# nrf7120E_enga_application register map
Vendor: Nordic Semiconductor; Series: nrf71; File version: 1
CPU: CM33 r0p4, little endian, MPU, FPU, 3 interrupt priority bits, 270 interrupts, 4 SAU regions
Registers are 32-bit, read-write, reset 0x0 unless marked. A register's access mark holds for its fields unless they carry their own. Offsets are from the block's base; [hi:lo] are bit positions; {n}, {i} and the like mark numbered series; 'fields as' and 'values as' point back to an identical list.

## GLOBAL_TAD_NS — Trace and debug control 0
Base 0x40053000
Same registers: GLOBAL_TAD_S 0x50053000
0x400 SYSPWRUPREQ — System power-up request
  [0] ACTIVE — Activate power-up request
    0=NotActive (Power-up request not active); 1=Active (Power-up request active)
0x404 DBGPWRUPREQ — Debug power-up request
  fields as SYSPWRUPREQ
0x500 ENABLE — Enable debug domain and acquire selected GPIOs
  [0] ENABLE
    0=DISABLED (Disable debug domain and release selected GPIOs); 1=ENABLED (Enable debug domain and acquire selected GPIOs)
0x518 TRACEPORTSPEED
  [1:0] TRACEPORTSPEED — Trace port speed is divided from CPU clock. The TRACECLK pin output will be divided again by two from the trace port clock.
    0=DIV1 (Trace port speed equals CPU clock); 1=DIV2 (Trace port speed equals CPU clock divided by 2); 2=DIV4 (Trace port speed equals CPU clock divided by 4); 3=DIV32 (Trace port speed equals CPU clock divided by 32)
0x520 TINSTANCE — SW-DP Target instance
  [3:0] TINSTANCE — TINSTANCE bits are used in the SW-DP DLPIDR.TINSTANCE field.

## GLOBAL_AXONS_NS — Neural processing unit (NPU) 0
Base 0x40056000
Same registers: GLOBAL_AXONS_S 0x50056000
0x400 ENABLE — Enable AXONS.
  [0] EN — Enable
    0=Disabled (AXONS disabled (powered off).); 1=Enabled (AXONS enabled.)
0x404 STATUS ro
  [0] READY — AXONS ready
    0=NotReady (AXONS is not yet accessible); 1=Ready (AXONS is accessible)

## GLOBAL_EGU00_NS — Event generator unit 0
Base 0x40058000
Same registers: GLOBAL_EGU10_NS 0x40087000, GLOBAL_EGU20_NS 0x400C9000, GLOBAL_EGU00_S 0x50058000, GLOBAL_EGU10_S 0x50087000, GLOBAL_EGU20_S 0x500C9000
{0x0+4i} TASKS_TRIGGER[{i}] (i=0..15) wo — Description collection: Trigger n for triggering the corresponding TRIGGERED[n] event
  [0] TASKS_TRIGGER — Trigger n for triggering the corresponding TRIGGERED[n] event
    1=Trigger task
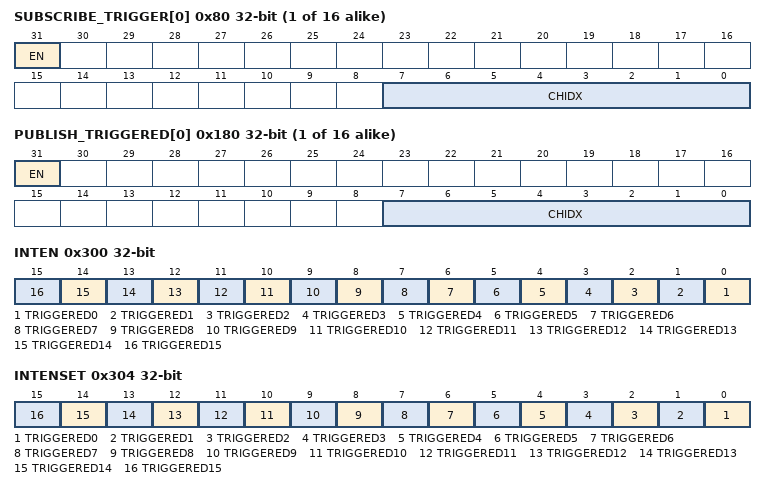
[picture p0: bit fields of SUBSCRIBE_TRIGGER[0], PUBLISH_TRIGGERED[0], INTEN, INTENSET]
{0x80+4i} SUBSCRIBE_TRIGGER[{i}] (i=0..15) — Description collection: Subscribe configuration for task TRIGGER[n]
  [31] EN
    0=Disabled (Disable subscription); 1=Enabled (Enable subscription)
  [7:0] CHIDX — DPPI channel that task TRIGGER[n] will subscribe to
{0x100+4i} EVENTS_TRIGGERED[{i}] (i=0..15) — Description collection: Event number n generated by triggering the corresponding TRIGGER[n] task
  [0] EVENTS_TRIGGERED — Event number n generated by triggering the corresponding TRIGGER[n] task
    0=NotGenerated (Event not generated); 1=Generated (Event generated)
{0x180+4i} PUBLISH_TRIGGERED[{i}] (i=0..15) — Description collection: Publish configuration for event TRIGGERED[n]
  [31] EN
    0=Disabled (Disable publishing); 1=Enabled (Enable publishing)
  [7:0] CHIDX — DPPI channel that event TRIGGERED[n] will publish to
0x300 INTEN — Enable or disable interrupt
  [all] fields
    0=Disabled; 1=Enabled
  [n] TRIGGERED{n} (n=0..15) — Enable or disable interrupt for event TRIGGERED[{n}]
0x304 INTENSET — Enable interrupt
  [all] fields
    on read: 0=Disabled (Read: Disabled); 1=Enabled (Read: Enabled) | on write: 1=Set (Enable)
  [n] TRIGGERED{n} write-1-sets (n=0..15) — Write '1' to enable interrupt for event TRIGGERED[{n}]
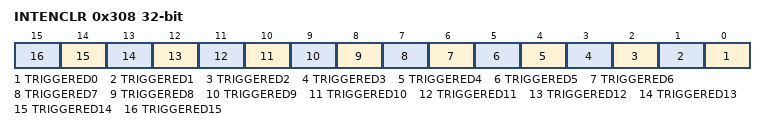
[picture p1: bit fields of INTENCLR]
0x308 INTENCLR — Disable interrupt
  [all] fields
    on read: 0=Disabled (Read: Disabled); 1=Enabled (Read: Enabled) | on write: 1=Clear (Disable)
  [n] TRIGGERED{n} write-1-clears (n=0..15) — Write '1' to disable interrupt for event TRIGGERED[{n}]

## GLOBAL_CRACEN_S — CRACEN
Base 0x50059000
0x100 EVENTS_CRYPTOMASTER — Event indicating that interrupt triggered at Cryptomaster
  [0] EVENTS_CRYPTOMASTER
    0=NotGenerated (Event not generated); 1=Generated (Event generated)
0x104 EVENTS_RNG — Event indicating that interrupt triggered at RNG
  [0] EVENTS_RNG
    values as EVENTS_CRYPTOMASTER.EVENTS_CRYPTOMASTER
0x108 EVENTS_PKEIKG — Event indicating that interrupt triggered at PKE or IKG
  [0] EVENTS_PKEIKG
    values as EVENTS_CRYPTOMASTER.EVENTS_CRYPTOMASTER
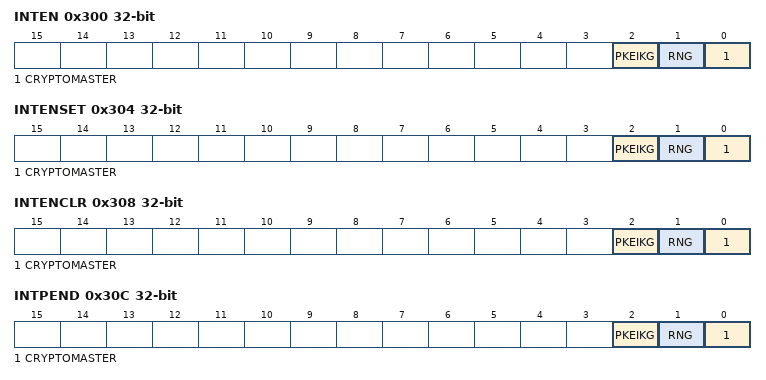
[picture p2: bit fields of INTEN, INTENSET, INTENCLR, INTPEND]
0x300 INTEN — Enable or disable interrupt
  [all] fields
    0=Disabled; 1=Enabled
  [2] PKEIKG — Enable or disable interrupt for event PKEIKG
  [1] RNG — Enable or disable interrupt for event RNG
  [0] CRYPTOMASTER — Enable or disable interrupt for event CRYPTOMASTER
0x304 INTENSET — Enable interrupt
  [all] fields
    on read: 0=Disabled (Read: Disabled); 1=Enabled (Read: Enabled) | on write: 1=Set (Enable)
  [2] PKEIKG write-1-sets — Write '1' to enable interrupt for event PKEIKG
  [1] RNG write-1-sets — Write '1' to enable interrupt for event RNG
  [0] CRYPTOMASTER write-1-sets — Write '1' to enable interrupt for event CRYPTOMASTER
0x308 INTENCLR — Disable interrupt
  [all] fields
    on read: 0=Disabled (Read: Disabled); 1=Enabled (Read: Enabled) | on write: 1=Clear (Disable)
  [2] PKEIKG write-1-clears — Write '1' to disable interrupt for event PKEIKG
  [1] RNG write-1-clears — Write '1' to disable interrupt for event RNG
  [0] CRYPTOMASTER write-1-clears — Write '1' to disable interrupt for event CRYPTOMASTER
0x30C INTPEND ro — Pending interrupts
  [all] fields
    on read: 0=NotPending (Read: Not pending); 1=Pending (Read: Pending)
  [2] PKEIKG — Read pending status of interrupt for event PKEIKG
  [1] RNG — Read pending status of interrupt for event RNG
  [0] CRYPTOMASTER — Read pending status of interrupt for event CRYPTOMASTER
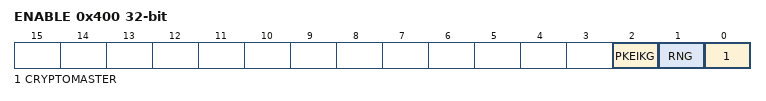
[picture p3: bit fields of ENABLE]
0x400 ENABLE — Enable CRACEN peripheral modules.
  [2] PKEIKG — Enable PKE and IKG
    0=Disabled (PKE and IKG disabled.); 1=Enabled (PKE and IKG enabled.)
  [1] RNG — Enable RNG
    0=Disabled (RNG disabled.); 1=Enabled (RNG enabled.)
  [0] CRYPTOMASTER — Enable cryptomaster
    0=Disabled (Cryptomaster disabled.); 1=Enabled (Cryptomaster enabled.)
0x404 SEEDVALID — Indicates the SEED register is valid. Writing this register has no effect.
  [0] VALID — Marks the SEED as valid
    0=Disabled (Valid disabled.); 1=Enabled (Valid enabled.)
{0x410+4i} SEED[{i}] (i=0..11) wo — Description collection: Seed word [n] for symmetric and asymmetric key generation. This register is only writable from KMU.
  [31:0] VAL — Seed value
0x440 SEEDLOCK — Indicates the access to the SEED register is locked. Writing this register has no effect.
  [0] ENABLE — Enable the lock
    0=Disabled (Lock disabled.); 1=Enabled (Lock enabled.)
0x444 PROTECTEDRAMLOCK — Lock the access to the protected RAM.
  fields as SEEDLOCK
